# CY8C3245AXI_158 register map
File version: 0.1
CY8C32
Registers are 8-bit, read-write, no defined reset value unless marked. A register's access mark holds for its fields unless they carry their own. Offsets are from the block's base; lines under a group give offsets from that group; [hi:lo] are bit positions; {n}, {i} and the like mark numbered series; 'fields as' and 'values as' point back to an identical list; <NAME> marks a mode.

## Memory map
0x00000000 UART_Debug — UART
0x00000000 UART_Servo — UART

## UART_Debug — UART
Base 0x00000000
0x6440 TX_UART_Debug_TX_DATA — TX Data Register
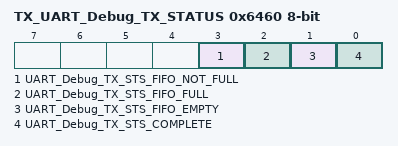
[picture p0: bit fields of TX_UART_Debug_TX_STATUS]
0x6460 TX_UART_Debug_TX_STATUS — TX status register
  [3] UART_Debug_TX_STS_FIFO_NOT_FULL ro, [2] UART_Debug_TX_STS_FIFO_FULL ro, [1] UART_Debug_TX_STS_FIFO_EMPTY ro, [0] UART_Debug_TX_STS_COMPLETE ro

## UART_Servo — UART
Base 0x00000000
0x6425 RX_UART_Servo_RX_ADDRESS1 — RX Address1 Register
0x6435 RX_UART_Servo_RX_ADDRESS2 — RX Address2 Register
0x6444 TX_UART_Servo_TX_DATA — TX Data Register
0x6445 RX_UART_Servo_RX_DATA — RX Data Register
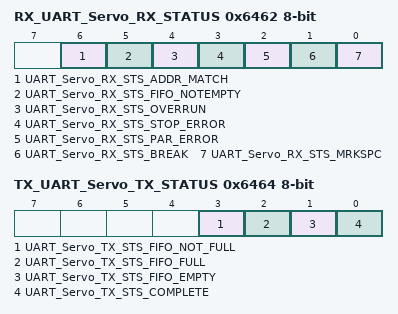
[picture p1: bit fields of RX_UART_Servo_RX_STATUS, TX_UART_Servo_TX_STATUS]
0x6462 RX_UART_Servo_RX_STATUS — RX status register
  [6] UART_Servo_RX_STS_ADDR_MATCH ro, [5] UART_Servo_RX_STS_FIFO_NOTEMPTY ro, [4] UART_Servo_RX_STS_OVERRUN ro, [3] UART_Servo_RX_STS_STOP_ERROR ro, [2] UART_Servo_RX_STS_PAR_ERROR ro, [1] UART_Servo_RX_STS_BREAK ro, [0] UART_Servo_RX_STS_MRKSPC ro
0x6464 TX_UART_Servo_TX_STATUS — TX status register
  [3] UART_Servo_TX_STS_FIFO_NOT_FULL ro, [2] UART_Servo_TX_STS_FIFO_FULL ro, [1] UART_Servo_TX_STS_FIFO_EMPTY ro, [0] UART_Servo_TX_STS_COMPLETE ro
